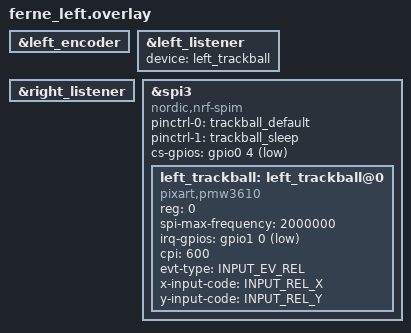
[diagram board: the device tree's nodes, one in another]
/*
 * Copyright (c) 2025 The ZMK Contributors
 *
 * SPDX-License-Identifier: MIT
 */

#include "ferne.dtsi"

&left_encoder {
    status = "okay";
};

&left_listener {
    status = "okay";
    device = <&left_trackball>;
};

&right_listener {
    status = "okay";
};

&spi3 {
	status = "okay";
	compatible = "nordic,nrf-spim";
	pinctrl-0 = <&trackball_default>;
	pinctrl-1 = <&trackball_sleep>;
	pinctrl-names = "default", "sleep";
	cs-gpios = <&gpio0 4 GPIO_ACTIVE_LOW>;  //"sel2"

	left_trackball: left_trackball@0 {
		status = "okay";
		compatible = "pixart,pmw3610";
		reg = <0>;
		spi-max-frequency = <2000000>;
		irq-gpios = <&gpio1 0 (GPIO_ACTIVE_LOW | GPIO_PULL_UP)>;
		cpi = <600>;
		evt-type = <INPUT_EV_REL>;
		x-input-code = <INPUT_REL_X>;
		y-input-code = <INPUT_REL_Y>;
	};
};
